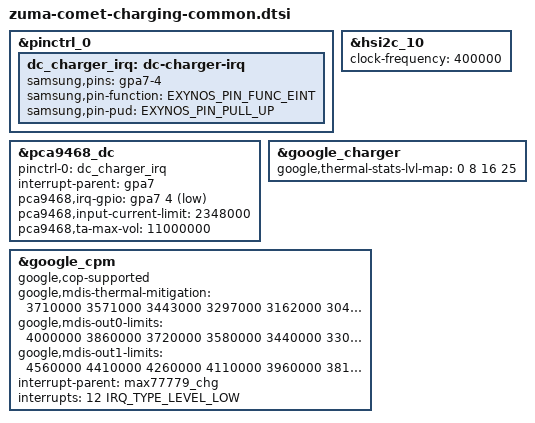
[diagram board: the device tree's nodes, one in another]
// SPDX-License-Identifier: GPL-2.0-only
/*
 * Zuma24 Battery device tree entries
 *
 * Copyright 2023 Google LLC
 *
 */
#include "google-dts-zuma/zuma-charging.dtsi"

&pinctrl_0 {

	dc_charger_irq: dc-charger-irq {
		samsung,pins = "gpa7-4"; /* XEINT_18 (PLC_INT_L) */
		samsung,pin-function = <EXYNOS_PIN_FUNC_EINT>;
		samsung,pin-pud = <EXYNOS_PIN_PULL_UP>;
	};
};

&hsi2c_10 {

	#address-cells = <1>;
	#size-cells = <0>;
	status = "okay";
	clock-frequency = <400000>;

	#include "google-dts-zuma/zuma-charge-pump-pca9468.dtsi"
};

&pca9468_dc {
	status = "okay";
	pinctrl-0 = <&dc_charger_irq>;

	interrupt-parent = <&gpa7>;
	pca9468,irq-gpio = <&gpa7 4 GPIO_ACTIVE_LOW>; /* PLC_INT_L */

	pca9468,input-current-limit = <2348000>; /* 4.696A max */

	pca9468,ta-max-vol = <11000000>; /* 11V */
};

&google_charger {
   google,thermal-stats-lvl-map = <0 8 16 25>;
};

&google_cpm {
	google,cop-supported;

	// thermal budgets
	google,mdis-thermal-mitigation =
	<3710000 3571000 3443000 3297000 3162000 3040000 2918000 2810000 2703000
	 2598000 2493000 2330000 2200000 2080000 1968000 1865000 1770000 1684000
	 1595000 1506000 1444000 1382000 1351000 1320000 1273000 1225000>;
	// PD+main-charger, WLC+main-charger
	google,mdis-out0-limits =
	<4000000 3860000 3720000 3580000 3440000 3300000 3160000 3020000 2880000
	 2740000 2600000 2460000 2320000 2180000 2040000 1900000 1760000 1620000
	 1480000 1340000 1200000 1060000 920000  780000  640000  500000
	 1100000 1100000 1100000 1100000 1100000 1100000 1100000 1100000 1100000
	 1100000 1100000 1100000 1050000 1000000 950000  900000  850000  800000
	 750000  700000  650000  600000  550000  500000  450000  400000>;
	// PPS_CP+pca94xx-mains, // WLC_CP+pca94xx-mains
	google,mdis-out1-limits =
	<4560000 4410000 4260000 4110000 3960000 3810000 3660000 3510000 3360000
	 3210000 3060000 2910000 2760000 2610000 2460000 2310000 2160000 2010000
	 1860000 1710000 1560000 1410000 1260000 1110000 1000000 1000000
	 4800000 4600000 4400000 4200000 4000000 3800000 3600000 3400000 3200000
	 3000000 2800000 2600000 2400000 2200000 2000000 1800000 1600000 1400000
	 1200000 1000000 900000  800000  700000  600000  500000  400000>;

	interrupt-parent = <&max77779_chg>;
	interrupts = <12 IRQ_TYPE_LEVEL_LOW>;
};
